VERSION ""

NS_ :

BS_:

BU_: XXX

BO_ 640 NEW_MSG_1: 8 XXX
 SG_ RPM? : 39|8@0+ (1,0) [0|255] "" XXX
 SG_ TRANSMISSION_TEMP? : 31|8@0+ (1,0) [0|255] "" XXX

BO_ 339 NEW_MSG_2: 8 XXX
 SG_ VEHICLE_SPEED : 23|8@0+ (1,0) [0|255] "" XXX

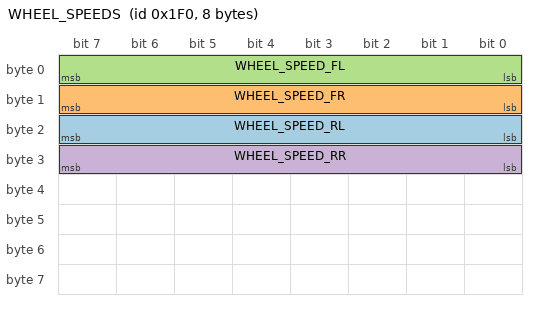
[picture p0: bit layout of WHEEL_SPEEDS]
BO_ 496 WHEEL_SPEEDS: 8 XXX
 SG_ WHEEL_SPEED_RL : 23|8@0+ (1,0) [0|255] "" XXX
 SG_ WHEEL_SPEED_FR : 15|8@0+ (1,0) [0|255] "" XXX
 SG_ WHEEL_SPEED_FL : 7|8@0+ (1,0) [0|255] "" XXX
 SG_ WHEEL_SPEED_RR : 31|8@0+ (1,0) [0|255] "" XXX

BO_ 809 NEW_MSG_4: 8 XXX

BO_ 1349 NEW_MSG_5: 8 XXX

BO_ 790 NEW_MSG_6: 8 XXX
 SG_ RPM? : 31|8@0+ (1,0) [0|255] "" XXX

BO_ 1088 NEW_MSG_7: 8 XXX
